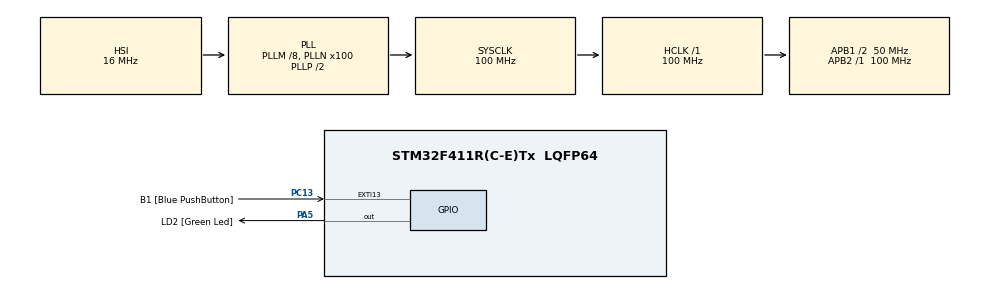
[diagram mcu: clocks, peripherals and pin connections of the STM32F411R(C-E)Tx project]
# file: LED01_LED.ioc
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Mcu.Family=STM32F4
Mcu.Name=STM32F411R(C-E)Tx
Mcu.Package=LQFP64
NVIC.PriorityGroup=NVIC_PRIORITYGROUP_0
PA13.GPIO_Label=TMS
PA13.Signal=SYS_JTMS-SWDIO
PA14.GPIO_Label=TCK
PA14.Signal=SYS_JTCK-SWCLK
PA2.GPIO_Label=USART_TX
PA2.Signal=USART2_TX
PA3.GPIO_Label=USART_RX
PA3.Signal=USART2_RX
PA5.GPIO_Label=LD2 [Green Led]
PA5.Signal=GPIO_Output
PB3.GPIO_Label=SWO
PB3.Signal=SYS_JTDO-SWO
PC13-ANTI_TAMP.GPIO_Label=B1 [Blue PushButton]
PC13-ANTI_TAMP.GPIO_ModeDefaultEXTI=GPIO_MODE_IT_FALLING
PC13-ANTI_TAMP.Signal=GPXTI13
PC14-OSC32_IN.Signal=RCC_OSC32_IN
PC15-OSC32_OUT.Signal=RCC_OSC32_OUT
PH0\ -\ OSC_IN.Signal=RCC_OSC_IN
PH1\ -\ OSC_OUT.Signal=RCC_OSC_OUT
ProjectManager.HeapSize=0x200
ProjectManager.StackSize=0x400
ProjectManager.TargetToolchain=MDK-ARM V5
RCC.48MHZClocksFreq_Value=50000000
RCC.AHBFreq_Value=100000000
RCC.APB1CLKDivider=RCC_HCLK_DIV2
RCC.APB1Freq_Value=50000000
RCC.APB1TimFreq_Value=100000000
RCC.APB2Freq_Value=100000000
RCC.APB2TimFreq_Value=100000000
RCC.CortexFreq_Value=100000000
RCC.FLatency-AdvancedSettings=FLASH_LATENCY_3
RCC.HCLKFreq_Value=100000000
RCC.HSE_VALUE=8000000
RCC.HSI_VALUE=16000000
RCC.LSE_VALUE=32768
RCC.PLLM=8
RCC.PLLN=100
RCC.SYSCLKFreq_VALUE=100000000
RCC.SYSCLKSource=RCC_SYSCLKSOURCE_PLLCLK
RCC.VCOOutputFreq_Value=200000000
board=NUCLEO-F411RE

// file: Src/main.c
/* USER CODE BEGIN Header */
/**
  ******************************************************************************
  * @file           : main.c
  * @brief          : Main program body
  ******************************************************************************
  * @attention
  *
  * <h2><center>&copy; Copyright (c) 2019 STMicroelectronics.
  * All rights reserved.</center></h2>
  *
  * This software component is licensed by ST under BSD 3-Clause license,
  * the "License"; You may not use this file except in compliance with the
  * License. You may obtain a copy of the License at:
  *                        opensource.org/licenses/BSD-3-Clause
  *
  ******************************************************************************
  */
/* USER CODE END Header */

#include "main.h"
#include "gpio.h"

/* USER CODE BEGIN PV */
uint8_t num=0;

/* USER CODE END PV */

void SystemClock_Config(void);
/* USER CODE BEGIN PFP */
void delay (uint32_t);
/* USER CODE END PFP */

int main(void)
{

  /* MCU Configuration--------------------------------------------------------*/

  /* Reset of all peripherals, Initializes the Flash interface and the Systick. */
  HAL_Init();

  /* Configure the system clock */
  SystemClock_Config();

  /* Initialize all configured peripherals */
  MX_GPIO_Init();

  /* Infinite loop */
  while (1)
  {

    /* USER CODE BEGIN 3 */
		if(num<7)
			num++;
		else
			num = 0;
		//Toggle User LED on PA5
		//HAL_GPIO_TogglePin(GPIOA, GPIO_PIN_5);
		GPIOA->ODR ^= GPIO_PIN_5;
		//delay 500 ms
		//HAL_Delay(500);
		delay(500);
  }
  /* USER CODE END 3 */
}

void SystemClock_Config(void)
{
  RCC_OscInitTypeDef RCC_OscInitStruct = {0};
  RCC_ClkInitTypeDef RCC_ClkInitStruct = {0};

  /** Configure the main internal regulator output voltage
  */
  __HAL_RCC_PWR_CLK_ENABLE();
  __HAL_PWR_VOLTAGESCALING_CONFIG(PWR_REGULATOR_VOLTAGE_SCALE1);
  /** Initializes the CPU, AHB and APB busses clocks
  */
  RCC_OscInitStruct.OscillatorType = RCC_OSCILLATORTYPE_HSI;
  RCC_OscInitStruct.HSIState = RCC_HSI_ON;
  RCC_OscInitStruct.HSICalibrationValue = RCC_HSICALIBRATION_DEFAULT;
  RCC_OscInitStruct.PLL.PLLState = RCC_PLL_ON;
  RCC_OscInitStruct.PLL.PLLSource = RCC_PLLSOURCE_HSI;
  RCC_OscInitStruct.PLL.PLLM = 8;
  RCC_OscInitStruct.PLL.PLLN = 100;
  RCC_OscInitStruct.PLL.PLLP = RCC_PLLP_DIV2;
  RCC_OscInitStruct.PLL.PLLQ = 4;
  if (HAL_RCC_OscConfig(&RCC_OscInitStruct) != HAL_OK)
  {
    Error_Handler();
  }
  /** Initializes the CPU, AHB and APB busses clocks
  */
  RCC_ClkInitStruct.ClockType = RCC_CLOCKTYPE_HCLK|RCC_CLOCKTYPE_SYSCLK
                              |RCC_CLOCKTYPE_PCLK1|RCC_CLOCKTYPE_PCLK2;
  RCC_ClkInitStruct.SYSCLKSource = RCC_SYSCLKSOURCE_PLLCLK;
  RCC_ClkInitStruct.AHBCLKDivider = RCC_SYSCLK_DIV1;
  RCC_ClkInitStruct.APB1CLKDivider = RCC_HCLK_DIV2;
  RCC_ClkInitStruct.APB2CLKDivider = RCC_HCLK_DIV1;

  if (HAL_RCC_ClockConfig(&RCC_ClkInitStruct, FLASH_LATENCY_3) != HAL_OK)
  {
    Error_Handler();
  }
}

/* USER CODE BEGIN 4 */
void delay (uint32_t ms){
	volatile uint32_t i,j;

	for(i = 0; i <= ms; i++)
		for(j=0; j<=14300;j++)
			;
	return;
}

/* USER CODE END 4 */

void Error_Handler(void)
{
}

/************************ (C) COPYRIGHT STMicroelectronics *****END OF FILE****/
